# ESP32S31_RADIO register map
Vendor: Espressif; Series: ESP32-S31; File version: 3.52
Registers are 32-bit, read-write, no defined reset value unless marked. A register's access mark holds for its fields unless they carry their own. Offsets are from the block's base; [hi:lo] are bit positions; {n}, {i} and the like mark numbered series; 'fields as' and 'values as' point back to an identical list.

## WIFI_MAC_RX_DMA — Descriptor-walker registers recovered from complete rev0 ROM leaves and qualified with the open driver's rotating 32-entry RX ring.
Base 0x20104000
0x7C WORD_007C_OPAQUE — Opaque: meaning not established. Complete mac_rxbuf_init clears the low byte immediately before publishing the descriptor base. Individual bit meanings are unknown.
  [7:0] BITS_0_7_OPAQUE — Opaque: meaning not established.
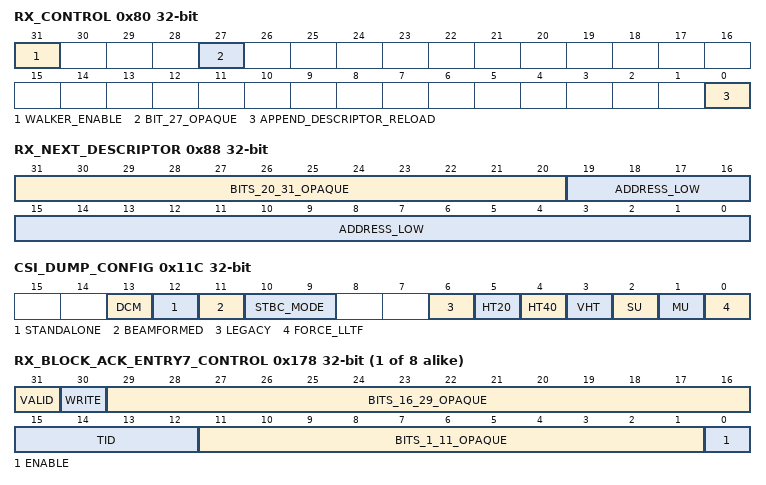
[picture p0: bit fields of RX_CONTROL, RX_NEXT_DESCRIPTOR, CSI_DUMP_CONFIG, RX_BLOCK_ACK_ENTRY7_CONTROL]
0x80 RX_CONTROL — Project-assigned name. RX descriptor-walker gate, hardware-beacon reload selection and live-list append doorbell.
  [31] WALKER_ENABLE — Project-assigned name. Set by libpp[hal_mac.o]::hal_mac_rx_enable and cleared by libpp[hal_mac.o]::hal_mac_rx_disable; gates the RX descriptor walker.
  [27] BIT_27_OPAQUE — Opaque: meaning not established. Complete hal_mac_set_rxbuf_reload_use_hw_beacon_enable sets bit 27 through one fresh-read RMW.
  [0] APPEND_DESCRIPTOR_RELOAD write-clears — Project-assigned name. Write one after publishing old_tail.next to make a prepared live-list append visible. Hardware clears the bit after accepting the append.
0x84 RX_DESCRIPTOR_BASE — Project-assigned name. Complete first-descriptor address. The ROM and blob leaves publish the unmasked 32-bit pointer when installing a cold or repaired frontier; the selected high-address window separately completes the hardware last/next descriptor observations.
  [31:0] ADDRESS — Project-assigned name.
0x88 RX_NEXT_DESCRIPTOR ro — Project-assigned name. Complete hardware current/next descriptor word. The low 20 bits are the reviewed address projection; meanings of bits 31:20 remain unknown. Complete ROM rom[]::wDev_AppendRxBlocks compares the entire 32-bit word with zero after reload completion, not only ADDRESS_LOW, before it may read LAST and repair RX_DESCRIPTOR_BASE.
  [31:20] BITS_20_31_OPAQUE — Opaque: meaning not established. Unassigned upper state retained by the complete-word zero predicate in rom[]::wDev_AppendRxBlocks. This is deliberately exposed separately from ADDRESS_LOW so production code never reconstructs or masks a register image.
  [19:0] ADDRESS_LOW — Project-assigned name.
0x8C RX_LAST_DESCRIPTOR ro — Project-assigned name. Low 20 bits of the last descriptor accepted by the RX walker.
  [19:0] ADDRESS_LOW — Project-assigned name.
0x11C CSI_DUMP_CONFIG — Project-assigned name. Complete esp_test_get_csi_dump_cfg reads every described field at 0x2010411c. Complete esp_test_set_csi_dump_cfg performs independent fresh-read RMW updates. Its BEAMFORMED update has a pinned vendor quirk: cfg[8] controls whether bit 11 is updated, but cfg[1] (MU) supplies the value. This SVD exposes the physical bit and does not reproduce that software bug.
  [13] DCM — Project-assigned name.
  [12] STANDALONE — Project-assigned name.
  [11] BEAMFORMED — Project-assigned name. Physical CSI-dump beamformed selector. The pinned vendor setter accidentally writes the MU argument when this field is selected; callers of the generated PAC write the actual bit directly.
  [10:9] STBC_MODE — Project-assigned name.
  [6] LEGACY — Project-assigned name.
  [5] HT20 — Project-assigned name.
  [4] HT40 — Project-assigned name.
  [3] VHT — Project-assigned name.
  [2] SU — Project-assigned name.
  [1] MU — Project-assigned name.
  [0] FORCE_LLTF — Project-assigned name.
0x178 RX_BLOCK_ACK_ENTRY{x}_CONTROL (x=7,6,5,4,3,2,1,0; step 0x24) — Project-assigned name. Configuration word in one of eight reverse-addressed ordinary receive BlockAck banks. Physical array index zero is logical hardware index seven; complete hal_agreement_add_rx_ba writes logical index zero at 0x20104274 and subtracts 0x24 per index. Delete clears VALID, clears both load bitmaps, sets VALID once, then clears this complete word.
  [31] VALID — Project-assigned name. Marks an installed entry. Complete delete clears and reasserts it around bitmap clearing before zeroing the entry.
  [30] WRITE — Project-assigned name. Complete add sets this bit together with ENABLE and VALID when publishing the entry configuration.
  [29:16] BITS_16_29_OPAQUE — Opaque: meaning not established. Bits preserved by reads but cleared by every reviewed zero-based ordinary-entry publication.
  [15:12] TID — Project-assigned name. Traffic identifier passed to complete hal_agreement_add_rx_ba without the extra staging path's index transform. The field is four bits wide, while complete ht_recv_action_ba_addba_request rejects values with bit three set and therefore admits TIDs zero through seven.
  [11:1] BITS_1_11_OPAQUE — Opaque: meaning not established. Bits preserved by reads but cleared by every reviewed zero-based ordinary-entry publication.
  [0] ENABLE — Project-assigned name. Complete add sets this bit in every installed ordinary receive BlockAck entry.
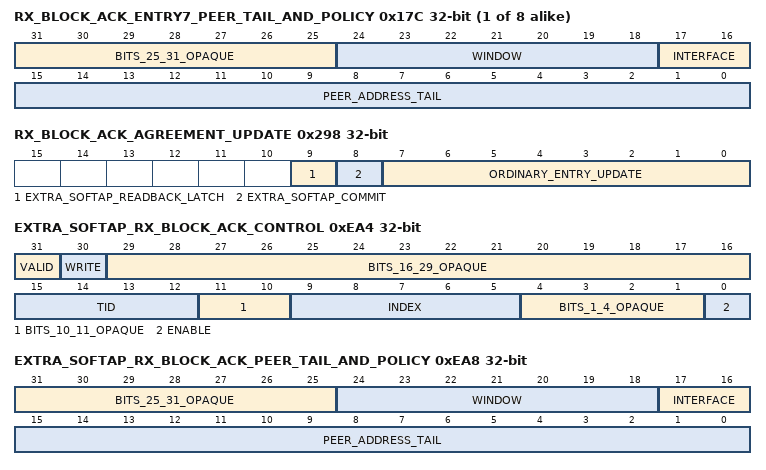
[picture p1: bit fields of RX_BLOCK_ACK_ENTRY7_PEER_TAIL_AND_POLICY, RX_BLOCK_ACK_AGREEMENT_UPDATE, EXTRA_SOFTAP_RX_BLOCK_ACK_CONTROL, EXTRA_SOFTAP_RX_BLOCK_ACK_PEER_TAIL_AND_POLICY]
0x17C RX_BLOCK_ACK_ENTRY{x}_PEER_TAIL_AND_POLICY (x=7,6,5,4,3,2,1,0; step 0x24) — Project-assigned name. Peer MAC bytes four and five, interface number and receive reorder-window size in one reverse-addressed ordinary receive BlockAck bank. Complete vendor ampdu_rx_start limits the protocol agreement by the peer request and configured receive window; its ordinary hardware-activation branch independently passes the constant 64 to ic_add_rx_ba. Complete hal_agreement_add_rx_ba then stores that value in WINDOW.
  [31:25] BITS_25_31_OPAQUE — Opaque: meaning not established. Bits cleared by every reviewed zero-based ordinary-entry policy publication.
  [24:18] WINDOW — Project-assigned name. Seven-bit hardware receive BlockAck window. The normal vendor ordinary-STA activation path publishes 64.
  [17:16] INTERFACE — Project-assigned name.
  [15:0] PEER_ADDRESS_TAIL — Project-assigned name.
0x180 RX_BLOCK_ACK_ENTRY{x}_PEER_HEAD (x=7,6,5,4,3,2,1,0; step 0x24) — Project-assigned name. Peer MAC bytes zero through three in little-endian order in one reverse-addressed ordinary receive BlockAck bank.
  [31:0] PEER_ADDRESS_HEAD — Project-assigned name.
0x184 RX_BLOCK_ACK_ENTRY{x}_CURRENT_SEQUENCE (x=7,6,5,4,3,2,1,0; step 0x24) ro — Project-assigned name. Hardware-maintained twelve-bit receive/reorder sequence state. Complete libpp[hal_ampdu.o]::hal_ba_session_store snapshots this word and complete libpp[hal_ampdu.o]::hal_ba_session_restore copies its saved low twelve bits into START_SEQUENCE_LOAD.
  [11:0] SEQUENCE — Project-assigned name.
0x188 RX_BLOCK_ACK_ENTRY{x}_START_SEQUENCE_LOAD (x=7,6,5,4,3,2,1,0; step 0x24) — Project-assigned name. Twelve-bit starting sequence written by complete add/reset/restore leaves. This is the software load word paired with the adjacent hardware-maintained CURRENT_SEQUENCE word.
  [11:0] SEQUENCE — Project-assigned name.
0x18C RX_BLOCK_ACK_ENTRY{x}_BITMAP_LOW_STATUS (x=7,6,5,4,3,2,1,0; step 0x24) ro — Project-assigned name. Hardware-maintained low reorder bitmap. Complete libpp[hal_ampdu.o]::hal_ba_session_store snapshots this word and restore copies it into BITMAP_LOW_LOAD while VALID is clear.
  [31:0] BITMAP — Project-assigned name. Low 32 bits of the hardware-maintained receive reorder bitmap.
0x190 RX_BLOCK_ACK_ENTRY{x}_BITMAP_LOW_LOAD (x=7,6,5,4,3,2,1,0; step 0x24) — Project-assigned name. Software load word for the low reorder bitmap. Complete add and delete clear it; complete session restore writes the saved low status bitmap here while VALID is clear.
  [31:0] BITMAP — Project-assigned name. Low 32 bits of the software-loaded receive reorder bitmap.
0x194 RX_BLOCK_ACK_ENTRY{x}_BITMAP_HIGH_STATUS (x=7,6,5,4,3,2,1,0; step 0x24) ro — Project-assigned name. Hardware-maintained high reorder bitmap. Complete libpp[hal_ampdu.o]::hal_ba_session_store snapshots this word and restore copies it into BITMAP_HIGH_LOAD while VALID is clear.
  [31:0] BITMAP — Project-assigned name. High 32 bits of the hardware-maintained receive reorder bitmap.
0x198 RX_BLOCK_ACK_ENTRY{x}_BITMAP_HIGH_LOAD (x=7,6,5,4,3,2,1,0; step 0x24) — Project-assigned name. Software load word for the high reorder bitmap. Complete add and delete clear it; complete session restore writes the saved high status bitmap here while VALID is clear.
  [31:0] BITMAP — Project-assigned name. High 32 bits of the software-loaded receive reorder bitmap.
0x298 RX_BLOCK_ACK_AGREEMENT_UPDATE — Project-assigned name. Ordinary add/reset sets one of bits zero through seven for the corresponding direct bank. The independent extra-SoftAP staging path pulses bit eight to commit and uses bit nine to latch a selected entry for readback.
  [9] EXTRA_SOFTAP_READBACK_LATCH — Project-assigned name. Complete extra-SoftAP diagnostics, reset and delete set this bit while reading the entry selected in the staging control and clear it afterwards.
  [8] EXTRA_SOFTAP_COMMIT — Project-assigned name. Complete extra-SoftAP add/reset/delete pulses this bit high then low after filling the shared staging words.
  [7:0] ORDINARY_ENTRY_UPDATE — Project-assigned name. One update bit per reverse-addressed ordinary receive BlockAck bank. Complete add/reset performs a fresh-read OR with one shifted by the logical hardware index.
0xC68 WORD_0C68_OPAQUE — Opaque: meaning not established. Complete mac_rxbuf_init sets the low twenty bits before descriptor publication.
  [19:0] BITS_0_19_OPAQUE — Opaque: meaning not established.
0xC6C WORD_0C6C_OPAQUE — Opaque: meaning not established. Complete mac_rxbuf_init replaces the low twenty bits with four before selecting the descriptor high window.
  [19:0] BITS_0_19_OPAQUE — Opaque: meaning not established.
0xC70 RX_DESCRIPTOR_HIGH_WINDOW — Project-assigned name. High 12 descriptor-address bits shared with the low-address RX pointer registers. Complete mac_rxbuf_init and the open driver program 0x2f0 for internal SRAM.
  [31:20] ADDRESS_HIGH — Project-assigned name.
0xEA4 EXTRA_SOFTAP_RX_BLOCK_ACK_CONTROL — Project-assigned name. Shared staging and readback-control word used only by complete hal_agreement_*_extra_softap_rx_ba leaves. Ordinary STA/AP receive BlockAck agreements use the eight direct banks at 0x20104178..0x20104294 instead.
  [31] VALID — Project-assigned name.
  [30] WRITE — Project-assigned name.
  [29:16] BITS_16_29_OPAQUE — Opaque: meaning not established. Bits cleared by every reviewed zero-based extra-SoftAP control publication.
  [15:12] TID — Project-assigned name.
  [11:10] BITS_10_11_OPAQUE — Opaque: meaning not established. Bits cleared by every reviewed zero-based extra-SoftAP control publication.
  [9:5] INDEX — Project-assigned name.
  [4:1] BITS_1_4_OPAQUE — Opaque: meaning not established. Bits cleared by every reviewed zero-based extra-SoftAP control publication.
  [0] ENABLE — Project-assigned name.
0xEA8 EXTRA_SOFTAP_RX_BLOCK_ACK_PEER_TAIL_AND_POLICY — Project-assigned name. Shared extra-SoftAP staging word carrying peer MAC bytes four and five, interface and reorder-window size.
  [31:25] BITS_25_31_OPAQUE — Opaque: meaning not established. Bits cleared by every reviewed zero-based extra-SoftAP policy publication.
  [24:18] WINDOW — Project-assigned name.
  [17:16] INTERFACE — Project-assigned name.
  [15:0] PEER_ADDRESS_TAIL — Project-assigned name.
0xEAC EXTRA_SOFTAP_RX_BLOCK_ACK_PEER_HEAD — Project-assigned name. Shared extra-SoftAP staging word carrying peer MAC bytes zero through three in little-endian order.
  [31:0] PEER_ADDRESS_HEAD — Project-assigned name. Peer MAC address bytes zero through three in little-endian order.
0xEB0 EXTRA_SOFTAP_RX_BLOCK_ACK_START_SEQUENCE — Project-assigned name. Shared extra-SoftAP staging word carrying the twelve-bit starting sequence.
  [11:0] SEQUENCE — Project-assigned name.
0xEB4 EXTRA_SOFTAP_RX_BLOCK_ACK_BITMAP_LOW — Project-assigned name. Shared extra-SoftAP low receive/reorder bitmap staging word, cleared when installing or removing an entry.
  [31:0] BITMAP — Project-assigned name. Low 32 bits of the selected extra-SoftAP receive reorder bitmap.
0xEB8 EXTRA_SOFTAP_RX_BLOCK_ACK_BITMAP_HIGH — Project-assigned name. Shared extra-SoftAP high receive/reorder bitmap staging word, cleared when installing or removing an entry.
  [31:0] BITMAP — Project-assigned name. High 32 bits of the selected extra-SoftAP receive reorder bitmap.
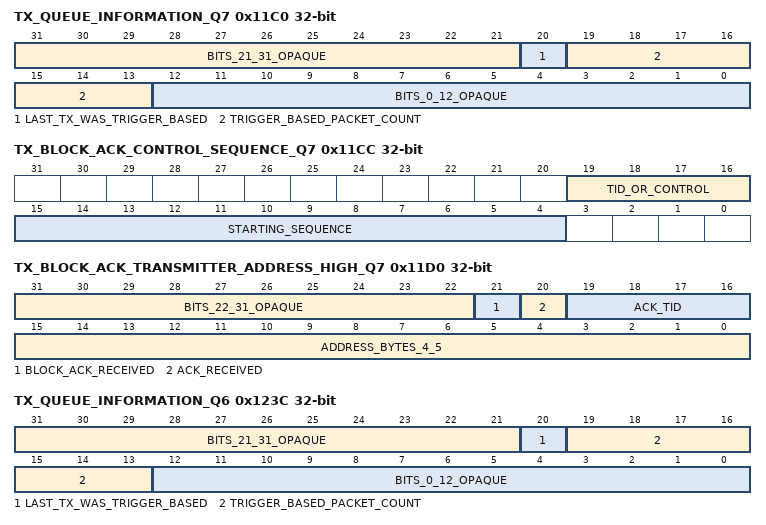
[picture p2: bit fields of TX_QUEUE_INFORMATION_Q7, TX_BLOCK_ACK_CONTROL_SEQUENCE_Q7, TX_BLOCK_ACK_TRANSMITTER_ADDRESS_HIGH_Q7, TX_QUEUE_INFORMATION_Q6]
0x11C0 TX_QUEUE_INFORMATION_Q7 ro — Project-assigned name. WDEVTXQ_TXINFO for reverse-addressed hardware queue 7.
  [31:21] BITS_21_31_OPAQUE — Opaque: meaning not established.
  [20] LAST_TX_WAS_TRIGGER_BASED — Project-assigned name.
  [19:13] TRIGGER_BASED_PACKET_COUNT — Project-assigned name.
  [12:0] BITS_0_12_OPAQUE — Opaque: meaning not established.
0x11C4 TX_BLOCK_ACK_BITMAP_HIGH_Q7 ro — Project-assigned name. WDEVTXQBA_BMHI for reverse-addressed hardware queue 7.
  [31:0] BITMAP — Project-assigned name.
0x11C8 TX_BLOCK_ACK_BITMAP_LOW_Q7 ro — Project-assigned name. WDEVTXQBA_BMLO for reverse-addressed hardware queue 7.
  [31:0] BITMAP — Project-assigned name.
0x11CC TX_BLOCK_ACK_CONTROL_SEQUENCE_Q7 ro — Project-assigned name. WDEVTXQBA_SSN: starting sequence bits 15:4 and TID/control bits 19:16 for queue 7.
  [19:16] TID_OR_CONTROL — Project-assigned name.
  [15:4] STARTING_SEQUENCE — Project-assigned name.
0x11D0 TX_BLOCK_ACK_TRANSMITTER_ADDRESS_HIGH_Q7 ro — Project-assigned name. WDEVTXQBA_TAHI; the blob identifies the low sixteen bits as the high two transmitter-address bytes and the upper fields as ACK/BlockAck result state.
  [31:22] BITS_22_31_OPAQUE — Opaque: meaning not established.
  [21] BLOCK_ACK_RECEIVED — Project-assigned name.
  [20] ACK_RECEIVED — Project-assigned name.
  [19:16] ACK_TID — Project-assigned name.
  [15:0] ADDRESS_BYTES_4_5 — Project-assigned name.
0x11D4 TX_BLOCK_ACK_TRANSMITTER_ADDRESS_LOW_Q7 ro — Project-assigned name. WDEVTXQBA_TALO; low four transmitter-address bytes.
  [31:0] ADDRESS_BYTES_0_3 — Project-assigned name.
0x123C TX_QUEUE_INFORMATION_Q6 ro — Project-assigned name. WDEVTXQ_TXINFO for reverse-addressed hardware queue 6.
  fields as TX_QUEUE_INFORMATION_Q7
0x1240 TX_BLOCK_ACK_BITMAP_HIGH_Q6 ro — Project-assigned name. WDEVTXQBA_BMHI for reverse-addressed hardware queue 6.
  [31:0] BITMAP — Project-assigned name.
0x1244 TX_BLOCK_ACK_BITMAP_LOW_Q6 ro — Project-assigned name. WDEVTXQBA_BMLO for reverse-addressed hardware queue 6.
  [31:0] BITMAP — Project-assigned name.
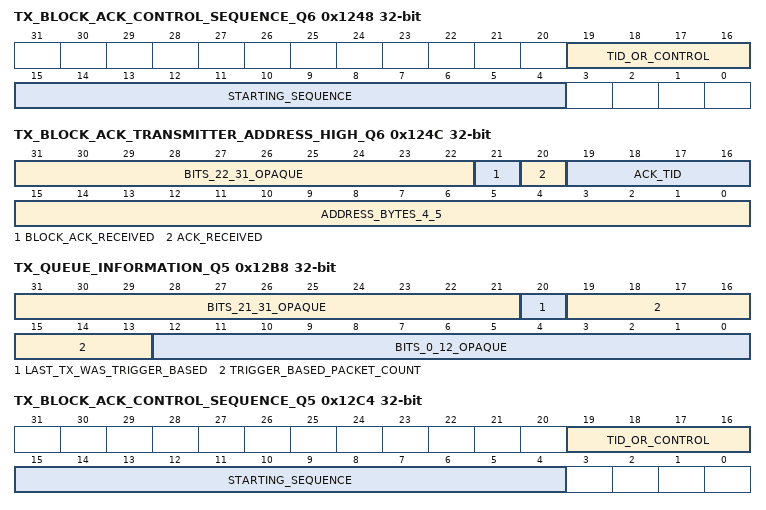
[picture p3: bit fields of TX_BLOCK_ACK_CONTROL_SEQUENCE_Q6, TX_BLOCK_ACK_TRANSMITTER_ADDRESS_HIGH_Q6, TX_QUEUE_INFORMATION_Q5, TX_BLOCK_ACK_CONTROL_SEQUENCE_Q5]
0x1248 TX_BLOCK_ACK_CONTROL_SEQUENCE_Q6 ro — Project-assigned name. WDEVTXQBA_SSN: starting sequence bits 15:4 and TID/control bits 19:16 for queue 6.
  fields as TX_BLOCK_ACK_CONTROL_SEQUENCE_Q7
0x124C TX_BLOCK_ACK_TRANSMITTER_ADDRESS_HIGH_Q6 ro — Project-assigned name. WDEVTXQBA_TAHI; the blob identifies the low sixteen bits as the high two transmitter-address bytes and the upper fields as ACK/BlockAck result state.
  fields as TX_BLOCK_ACK_TRANSMITTER_ADDRESS_HIGH_Q7
0x1250 TX_BLOCK_ACK_TRANSMITTER_ADDRESS_LOW_Q6 ro — Project-assigned name. WDEVTXQBA_TALO; low four transmitter-address bytes.
  [31:0] ADDRESS_BYTES_0_3 — Project-assigned name.
0x12B8 TX_QUEUE_INFORMATION_Q5 ro — Project-assigned name. WDEVTXQ_TXINFO for reverse-addressed hardware queue 5.
  fields as TX_QUEUE_INFORMATION_Q7
0x12BC TX_BLOCK_ACK_BITMAP_HIGH_Q5 ro — Project-assigned name. WDEVTXQBA_BMHI for reverse-addressed hardware queue 5.
  [31:0] BITMAP — Project-assigned name.
0x12C0 TX_BLOCK_ACK_BITMAP_LOW_Q5 ro — Project-assigned name. WDEVTXQBA_BMLO for reverse-addressed hardware queue 5.
  [31:0] BITMAP — Project-assigned name.
0x12C4 TX_BLOCK_ACK_CONTROL_SEQUENCE_Q5 ro — Project-assigned name. WDEVTXQBA_SSN: starting sequence bits 15:4 and TID/control bits 19:16 for queue 5.
  fields as TX_BLOCK_ACK_CONTROL_SEQUENCE_Q7
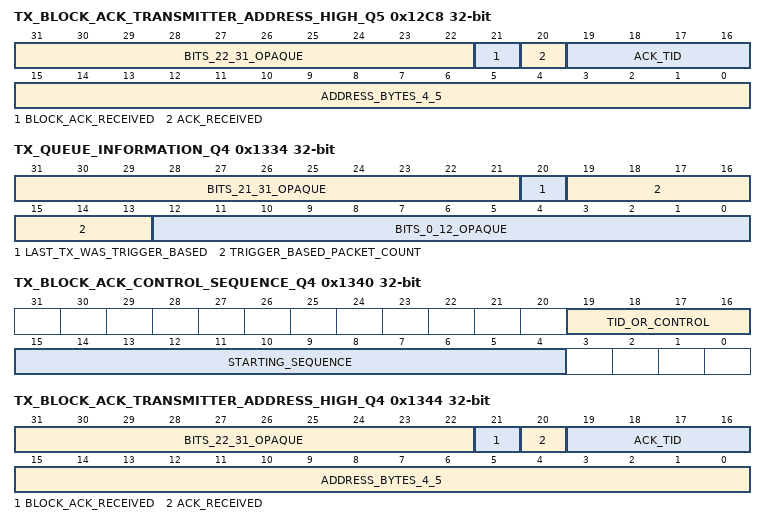
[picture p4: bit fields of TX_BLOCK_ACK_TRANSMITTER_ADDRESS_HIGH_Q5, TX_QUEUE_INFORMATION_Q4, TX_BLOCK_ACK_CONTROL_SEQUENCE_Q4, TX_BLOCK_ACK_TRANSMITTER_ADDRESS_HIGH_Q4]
0x12C8 TX_BLOCK_ACK_TRANSMITTER_ADDRESS_HIGH_Q5 ro — Project-assigned name. WDEVTXQBA_TAHI; the blob identifies the low sixteen bits as the high two transmitter-address bytes and the upper fields as ACK/BlockAck result state.
  fields as TX_BLOCK_ACK_TRANSMITTER_ADDRESS_HIGH_Q7
0x12CC TX_BLOCK_ACK_TRANSMITTER_ADDRESS_LOW_Q5 ro — Project-assigned name. WDEVTXQBA_TALO; low four transmitter-address bytes.
  [31:0] ADDRESS_BYTES_0_3 — Project-assigned name.
0x1334 TX_QUEUE_INFORMATION_Q4 ro — Project-assigned name. WDEVTXQ_TXINFO for reverse-addressed hardware queue 4.
  fields as TX_QUEUE_INFORMATION_Q7
0x1338 TX_BLOCK_ACK_BITMAP_HIGH_Q4 ro — Project-assigned name. WDEVTXQBA_BMHI for reverse-addressed hardware queue 4.
  [31:0] BITMAP — Project-assigned name.
0x133C TX_BLOCK_ACK_BITMAP_LOW_Q4 ro — Project-assigned name. WDEVTXQBA_BMLO for reverse-addressed hardware queue 4.
  [31:0] BITMAP — Project-assigned name.
0x1340 TX_BLOCK_ACK_CONTROL_SEQUENCE_Q4 ro — Project-assigned name. WDEVTXQBA_SSN: starting sequence bits 15:4 and TID/control bits 19:16 for queue 4.
  fields as TX_BLOCK_ACK_CONTROL_SEQUENCE_Q7
0x1344 TX_BLOCK_ACK_TRANSMITTER_ADDRESS_HIGH_Q4 ro — Project-assigned name. WDEVTXQBA_TAHI; the blob identifies the low sixteen bits as the high two transmitter-address bytes and the upper fields as ACK/BlockAck result state.
  fields as TX_BLOCK_ACK_TRANSMITTER_ADDRESS_HIGH_Q7
0x1348 TX_BLOCK_ACK_TRANSMITTER_ADDRESS_LOW_Q4 ro — Project-assigned name. WDEVTXQBA_TALO; low four transmitter-address bytes.
  [31:0] ADDRESS_BYTES_0_3 — Project-assigned name.
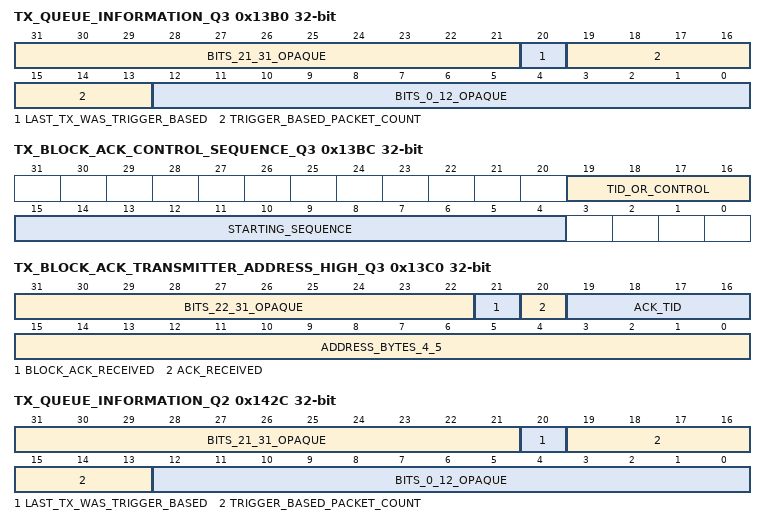
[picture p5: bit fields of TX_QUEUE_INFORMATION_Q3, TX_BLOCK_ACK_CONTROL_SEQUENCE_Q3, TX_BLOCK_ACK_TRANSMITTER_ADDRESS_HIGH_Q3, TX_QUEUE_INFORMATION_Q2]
0x13B0 TX_QUEUE_INFORMATION_Q3 ro — Project-assigned name. WDEVTXQ_TXINFO for reverse-addressed hardware queue 3.
  fields as TX_QUEUE_INFORMATION_Q7
0x13B4 TX_BLOCK_ACK_BITMAP_HIGH_Q3 ro — Project-assigned name. High 32 acknowledgement bits for completed hardware queue 3.
  [31:0] BITMAP — Project-assigned name.
0x13B8 TX_BLOCK_ACK_BITMAP_LOW_Q3 ro — Project-assigned name. Low 32 acknowledgement bits for completed hardware queue 3.
  [31:0] BITMAP — Project-assigned name.
0x13BC TX_BLOCK_ACK_CONTROL_SEQUENCE_Q3 ro — Project-assigned name. Control bits 19:16 and starting sequence bits 15:4 for completed hardware queue 3.
  fields as TX_BLOCK_ACK_CONTROL_SEQUENCE_Q7
0x13C0 TX_BLOCK_ACK_TRANSMITTER_ADDRESS_HIGH_Q3 ro — Project-assigned name. WDEVTXQBA_TAHI; high two transmitter-address bytes plus ACK/BlockAck result state.
  fields as TX_BLOCK_ACK_TRANSMITTER_ADDRESS_HIGH_Q7
0x13C4 TX_BLOCK_ACK_TRANSMITTER_ADDRESS_LOW_Q3 ro — Project-assigned name. WDEVTXQBA_TALO; low four transmitter-address bytes.
  [31:0] ADDRESS_BYTES_0_3 — Project-assigned name.
0x142C TX_QUEUE_INFORMATION_Q2 ro — Project-assigned name. WDEVTXQ_TXINFO for reverse-addressed hardware queue 2.
  fields as TX_QUEUE_INFORMATION_Q7
0x1430 TX_BLOCK_ACK_BITMAP_HIGH_Q2 ro — Project-assigned name. High 32 acknowledgement bits for completed hardware queue 2.
  [31:0] BITMAP — Project-assigned name.
0x1434 TX_BLOCK_ACK_BITMAP_LOW_Q2 ro — Project-assigned name. Low 32 acknowledgement bits for completed hardware queue 2.
  [31:0] BITMAP — Project-assigned name.
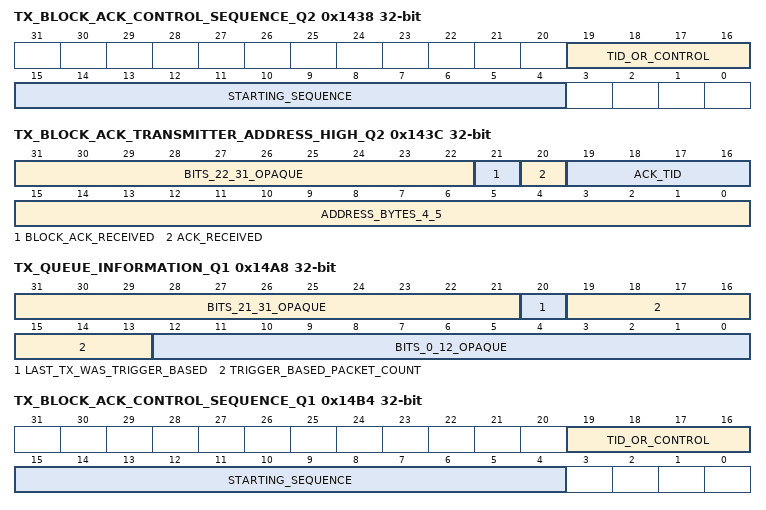
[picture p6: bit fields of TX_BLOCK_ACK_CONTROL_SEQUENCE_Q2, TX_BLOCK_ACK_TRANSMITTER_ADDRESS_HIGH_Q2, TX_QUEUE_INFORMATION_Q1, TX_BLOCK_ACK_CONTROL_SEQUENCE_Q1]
0x1438 TX_BLOCK_ACK_CONTROL_SEQUENCE_Q2 ro — Project-assigned name. Control bits 19:16 and starting sequence bits 15:4 for completed hardware queue 2.
  fields as TX_BLOCK_ACK_CONTROL_SEQUENCE_Q7
0x143C TX_BLOCK_ACK_TRANSMITTER_ADDRESS_HIGH_Q2 ro — Project-assigned name. WDEVTXQBA_TAHI; high two transmitter-address bytes plus ACK/BlockAck result state.
  fields as TX_BLOCK_ACK_TRANSMITTER_ADDRESS_HIGH_Q7
0x1440 TX_BLOCK_ACK_TRANSMITTER_ADDRESS_LOW_Q2 ro — Project-assigned name. WDEVTXQBA_TALO; low four transmitter-address bytes.
  [31:0] ADDRESS_BYTES_0_3 — Project-assigned name.
0x14A8 TX_QUEUE_INFORMATION_Q1 ro — Project-assigned name. WDEVTXQ_TXINFO for reverse-addressed hardware queue 1.
  fields as TX_QUEUE_INFORMATION_Q7
0x14AC TX_BLOCK_ACK_BITMAP_HIGH_Q1 ro — Project-assigned name. High 32 acknowledgement bits for completed hardware queue 1.
  [31:0] BITMAP — Project-assigned name.
0x14B0 TX_BLOCK_ACK_BITMAP_LOW_Q1 ro — Project-assigned name. Low 32 acknowledgement bits for completed hardware queue 1.
  [31:0] BITMAP — Project-assigned name.
0x14B4 TX_BLOCK_ACK_CONTROL_SEQUENCE_Q1 ro — Project-assigned name. Control bits 19:16 and starting sequence bits 15:4 for completed hardware queue 1.
  fields as TX_BLOCK_ACK_CONTROL_SEQUENCE_Q7
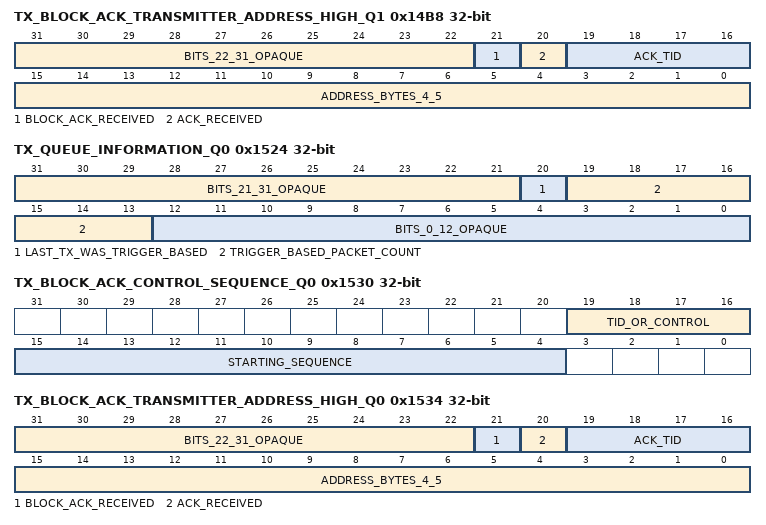
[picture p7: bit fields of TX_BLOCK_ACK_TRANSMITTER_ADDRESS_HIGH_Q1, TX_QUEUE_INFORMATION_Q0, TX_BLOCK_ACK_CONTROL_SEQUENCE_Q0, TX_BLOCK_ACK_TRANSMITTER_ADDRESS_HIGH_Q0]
0x14B8 TX_BLOCK_ACK_TRANSMITTER_ADDRESS_HIGH_Q1 ro — Project-assigned name. WDEVTXQBA_TAHI; high two transmitter-address bytes plus ACK/BlockAck result state.
  fields as TX_BLOCK_ACK_TRANSMITTER_ADDRESS_HIGH_Q7
0x14BC TX_BLOCK_ACK_TRANSMITTER_ADDRESS_LOW_Q1 ro — Project-assigned name. WDEVTXQBA_TALO; low four transmitter-address bytes.
  [31:0] ADDRESS_BYTES_0_3 — Project-assigned name.
0x1524 TX_QUEUE_INFORMATION_Q0 ro — Project-assigned name. WDEVTXQ_TXINFO for reverse-addressed hardware queue 0.
  fields as TX_QUEUE_INFORMATION_Q7
0x1528 TX_BLOCK_ACK_BITMAP_HIGH_Q0 ro — Project-assigned name. High 32 acknowledgement bits for completed hardware queue 0, sampled before acknowledging the completion edge.
  [31:0] BITMAP — Project-assigned name.
0x152C TX_BLOCK_ACK_BITMAP_LOW_Q0 ro — Project-assigned name. Low 32 acknowledgement bits for completed hardware queue 0, sampled before acknowledging the completion edge.
  [31:0] BITMAP — Project-assigned name.
0x1530 TX_BLOCK_ACK_CONTROL_SEQUENCE_Q0 ro — Project-assigned name. Control bits 19:16 and starting sequence bits 15:4 for completed hardware queue 0, sampled before acknowledging the completion edge.
  fields as TX_BLOCK_ACK_CONTROL_SEQUENCE_Q7
0x1534 TX_BLOCK_ACK_TRANSMITTER_ADDRESS_HIGH_Q0 ro — Project-assigned name. WDEVTXQBA_TAHI; high two transmitter-address bytes plus ACK/BlockAck result state for completed queue 0.
  fields as TX_BLOCK_ACK_TRANSMITTER_ADDRESS_HIGH_Q7
0x1538 TX_BLOCK_ACK_TRANSMITTER_ADDRESS_LOW_Q0 ro — Project-assigned name. WDEVTXQBA_TALO; low four transmitter-address bytes for completed queue 0.
  [31:0] ADDRESS_BYTES_0_3 — Project-assigned name.
